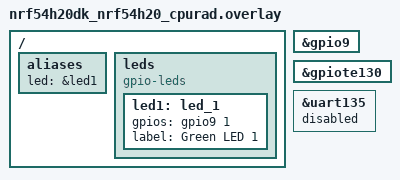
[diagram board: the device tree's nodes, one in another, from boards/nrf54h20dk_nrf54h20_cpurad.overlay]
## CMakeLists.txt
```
#
# Copyright (c) 2024 Nordic Semiconductor ASA
#
# SPDX-License-Identifier: LicenseRef-Nordic-5-Clause
#

cmake_minimum_required(VERSION 3.20.0)

find_package(Zephyr REQUIRED HINTS $ENV{ZEPHYR_BASE})
project(remote_sleep_forever)

target_sources(app PRIVATE src/main.c)
```

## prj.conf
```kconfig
CONFIG_PM=y
CONFIG_PM_DEVICE=y
CONFIG_PM_DEVICE_RUNTIME=y
CONFIG_POWEROFF=y
CONFIG_CONSOLE=n
CONFIG_UART_CONSOLE=n
CONFIG_SERIAL=n
CONFIG_GPIO=y
CONFIG_BOOT_BANNER=n
CONFIG_NCS_BOOT_BANNER=n
```

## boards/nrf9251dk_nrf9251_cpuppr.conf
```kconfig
CONFIG_PM=n
CONFIG_POWEROFF=n
```

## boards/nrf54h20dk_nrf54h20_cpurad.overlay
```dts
/*
 * Copyright (c) 2024 Nordic Semiconductor ASA
 *
 * SPDX-License-Identifier: LicenseRef-Nordic-5-Clause
 */

/ {
	aliases {
		led = &led1;
	};

	leds {
		compatible = "gpio-leds";

		led1: led_1 {
			gpios = <&gpio9 1 GPIO_ACTIVE_HIGH>;
			label = "Green LED 1";
		};
	};
};

&gpio9 {
	status = "okay";
};

&gpiote130 {
	status = "okay";
};

&uart135 {
	status = "disabled";
	/delete-property/ memory-regions;
};
```

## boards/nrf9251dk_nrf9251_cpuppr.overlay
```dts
/*
 * Copyright (c) 2026 Nordic Semiconductor ASA
 *
 * SPDX-License-Identifier: LicenseRef-Nordic-5-Clause
 */

/ {
	aliases {
		led = &led1;
	};

	leds {
		compatible = "gpio-leds";

		/* Move to other GPIO. */
		led1: led_1 {
			gpios = <&gpio2 1 GPIO_ACTIVE_HIGH>;
			label = "Custom GPIO";
		};
	};
};

&gpio2 {
	status = "okay";
};

&gpiote130 {
	status = "okay";
};

&uart132 {
	status = "disabled";
	/delete-property/ memory-regions;
};
```

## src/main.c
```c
/*
 * Copyright (c) 2024 Nordic Semiconductor ASA
 *
 * SPDX-License-Identifier: LicenseRef-Nordic-5-Clause
 */
#include <zephyr/kernel.h>
#include <zephyr/drivers/gpio.h>

static const struct gpio_dt_spec led = GPIO_DT_SPEC_GET(DT_ALIAS(led), gpios);


int main(void)
{
	gpio_pin_configure_dt(&led, GPIO_OUTPUT_INACTIVE);
	k_sleep(K_FOREVER);

	return 0;
}
```
